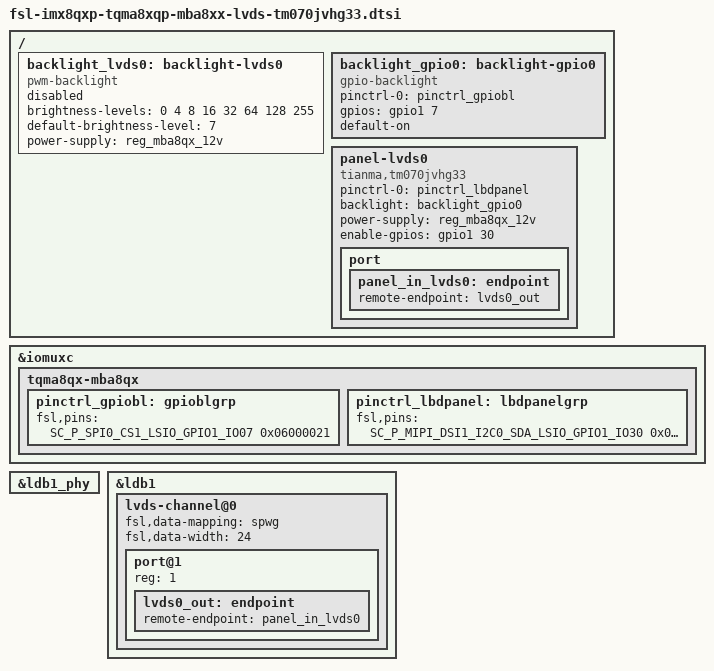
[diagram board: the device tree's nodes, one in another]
/*
 * Copyright 2018 TQ Systems GmbH
 *
 * This program is free software; you can redistribute it and/or
 * modify it under the terms of the GNU General Public License
 * as published by the Free Software Foundation; either version 2
 * of the License, or (at your option) any later version.
 *
 * This program is distributed in the hope that it will be useful,
 * but WITHOUT ANY WARRANTY; without even the implied warranty of
 * MERCHANTABILITY or FITNESS FOR A PARTICULAR PURPOSE.  See the
 * GNU General Public License for more details.
 */

/ {
	backlight_lvds0: backlight-lvds0 {
		compatible = "pwm-backlight";
		/* TODO: not enable yet */
		/* pwms = <&pwm4 0 5000000>; */
		brightness-levels = <0 4 8 16 32 64 128 255>;
		default-brightness-level = <7>;
		power-supply = <&reg_mba8qx_12v>;
		status = "disabled";
	};

	/* TODO: use pwm backlight as soon as drivers are available */
	backlight_gpio0: backlight-gpio0 {
		compatible = "gpio-backlight";
		pinctrl-names = "default";
		pinctrl-0 = <&pinctrl_gpiobl>;
		gpios = <&gpio1 7 GPIO_ACTIVE_HIGH>;
		default-on;
		status = "okay";
	};

	panel-lvds0 {
		compatible = "tianma,tm070jvhg33", "tianma,tm070jdhg30";
		pinctrl-names = "default";
		pinctrl-0 = <&pinctrl_lbdpanel>;
		backlight = <&backlight_gpio0>;
		power-supply = <&reg_mba8qx_12v>;
		enable-gpios = <&gpio1 30 0>;
		status = "okay";

		port {
			panel_in_lvds0: endpoint {
				remote-endpoint = <&lvds0_out>;
			};
		};
	};
};

&iomuxc {
	tqma8qx-mba8qx {

		pinctrl_gpiobl: gpioblgrp {
			fsl,pins = <
				/* TODO: LCD_CONTRAST -> DSI PMW */
				SC_P_SPI0_CS1_LSIO_GPIO1_IO07		0x06000021
			>;
		};

		pinctrl_lbdpanel: lbdpanelgrp {
			fsl,pins = <
				/* TODO: LCD_BLT_EN -> DSI_GPIO */
				SC_P_MIPI_DSI1_I2C0_SDA_LSIO_GPIO1_IO30	0x06000021
			>;
		};
	};
};

&ldb1_phy {
	status = "okay";
};

&ldb1 {
	status = "okay";

	lvds-channel@0 {
		fsl,data-mapping = "spwg";
		fsl,data-width = <24>;
		status = "okay";

		port@1 {
			reg = <1>;

			lvds0_out: endpoint {
				remote-endpoint = <&panel_in_lvds0>;
			};
		};
	};
};

